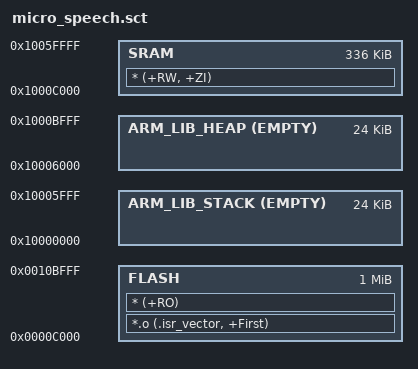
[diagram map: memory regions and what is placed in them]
;******************************************************************************
;
; hello_world.sct
;
; Scatter file for Keil linker configuration.
;
;******************************************************************************

;******************************************************************************
;
; ${copyright}
;
; This is part of revision ${version} of the AmbiqSuite Development Package.
;
;******************************************************************************
LR_1 0x0000C000
{
    FLASH 0x0000C000 0x00100000
    {
        *.o (.isr_vector, +First)
        * (+RO)
    }

    ARM_LIB_STACK 0x10000000 ALIGN 8 EMPTY 0x00006000
    {
    }
	
    ARM_LIB_HEAP 0x10000000+0x6000 ALIGN 8 EMPTY 0x00006000
    {
    }
	
    SRAM 0x10000000+0x0000C000 0x00060000-0x0000C000
    {
        * (+RW, +ZI)
    }
}

